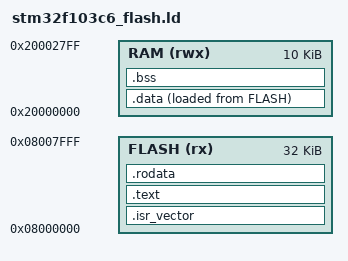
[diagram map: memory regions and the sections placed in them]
/*
 * Linker script for STM32F103C6 (32 KB Flash, 10 KB SRAM)
 */

MEMORY
{
  FLASH (rx) : ORIGIN = 0x08000000, LENGTH = 32K
  RAM (rwx)  : ORIGIN = 0x20000000, LENGTH = 10K
}

_estack = ORIGIN(RAM) + LENGTH(RAM);

SECTIONS
{
  .isr_vector :
  {
    . = ALIGN(4);
    KEEP(*(.isr_vector))
    . = ALIGN(4);
  } >FLASH

  .text :
  {
    . = ALIGN(4);
    *(.text)
    *(.text*)
    . = ALIGN(4);
  } >FLASH

  .rodata :
  {
    . = ALIGN(4);
    *(.rodata)
    *(.rodata*)
    . = ALIGN(4);
  } >FLASH

  . = ALIGN(4);
  _sidata = LOADADDR(.data);

  .data :
  {
    . = ALIGN(4);
    _sdata = .;
    *(.data)
    *(.data*)
    . = ALIGN(4);
    _edata = .;
  } >RAM AT> FLASH

  .bss :
  {
    . = ALIGN(4);
    _sbss = .;
    __bss_start__ = .;
    *(.bss)
    *(.bss*)
    *(COMMON)
    . = ALIGN(4);
    _ebss = .;
    __bss_end__ = .;
  } >RAM

  /* Stabs debugging sections. */
  .stab          0 : { *(.stab) }
  .stabstr       0 : { *(.stabstr) }
  .stab.excl     0 : { *(.stab.excl) }
  .stab.exclstr  0 : { *(.stab.exclstr) }
  .stab.index    0 : { *(.stab.index) }
  .stab.indexstr 0 : { *(.stab.indexstr) }
  .comment       0 : { *(.comment) }
  .debug          0 : { *(.debug) }
  .debug_info     0 : { *(.debug_info) }
  .debug_abbrev   0 : { *(.debug_abbrev) }
  .debug_aranges  0 : { *(.debug_aranges) }
  .debug_ranges   0 : { *(.debug_ranges) }
  .debug_line     0 : { *(.debug_line) }
  .debug_str      0 : { *(.debug_str) }
  .debug_loc      0 : { *(.debug_loc) }
  .debug_macinfo  0 : { *(.debug_macinfo) }
  .debug_pubnames 0 : { *(.debug_pubnames) }
  .debug_pubtypes 0 : { *(.debug_pubtypes) }
  .debug_frame    0 : { *(.debug_frame) }
  .debug_line_str 0 : { *(.debug_line_str) }
  .debug_loclists 0 : { *(.debug_loclists) }
  .debug_rnglists 0 : { *(.debug_rnglists) }
  .debug_gnu_pubnames 0 : { *(.debug_gnu_pubnames) }
  .debug_gnu_pubtypes 0 : { *(.debug_gnu_pubtypes) }
  .debug_str_offsets 0 : { *(.debug_str_offsets) }
  .debug_sup 0 : { *(.debug_sup) }
  .debug_names 0 : { *(.debug_names) }
  .debug_addr 0 : { *(.debug_addr) }
  .ARM.attributes 0 : { *(.ARM.attributes) }
}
